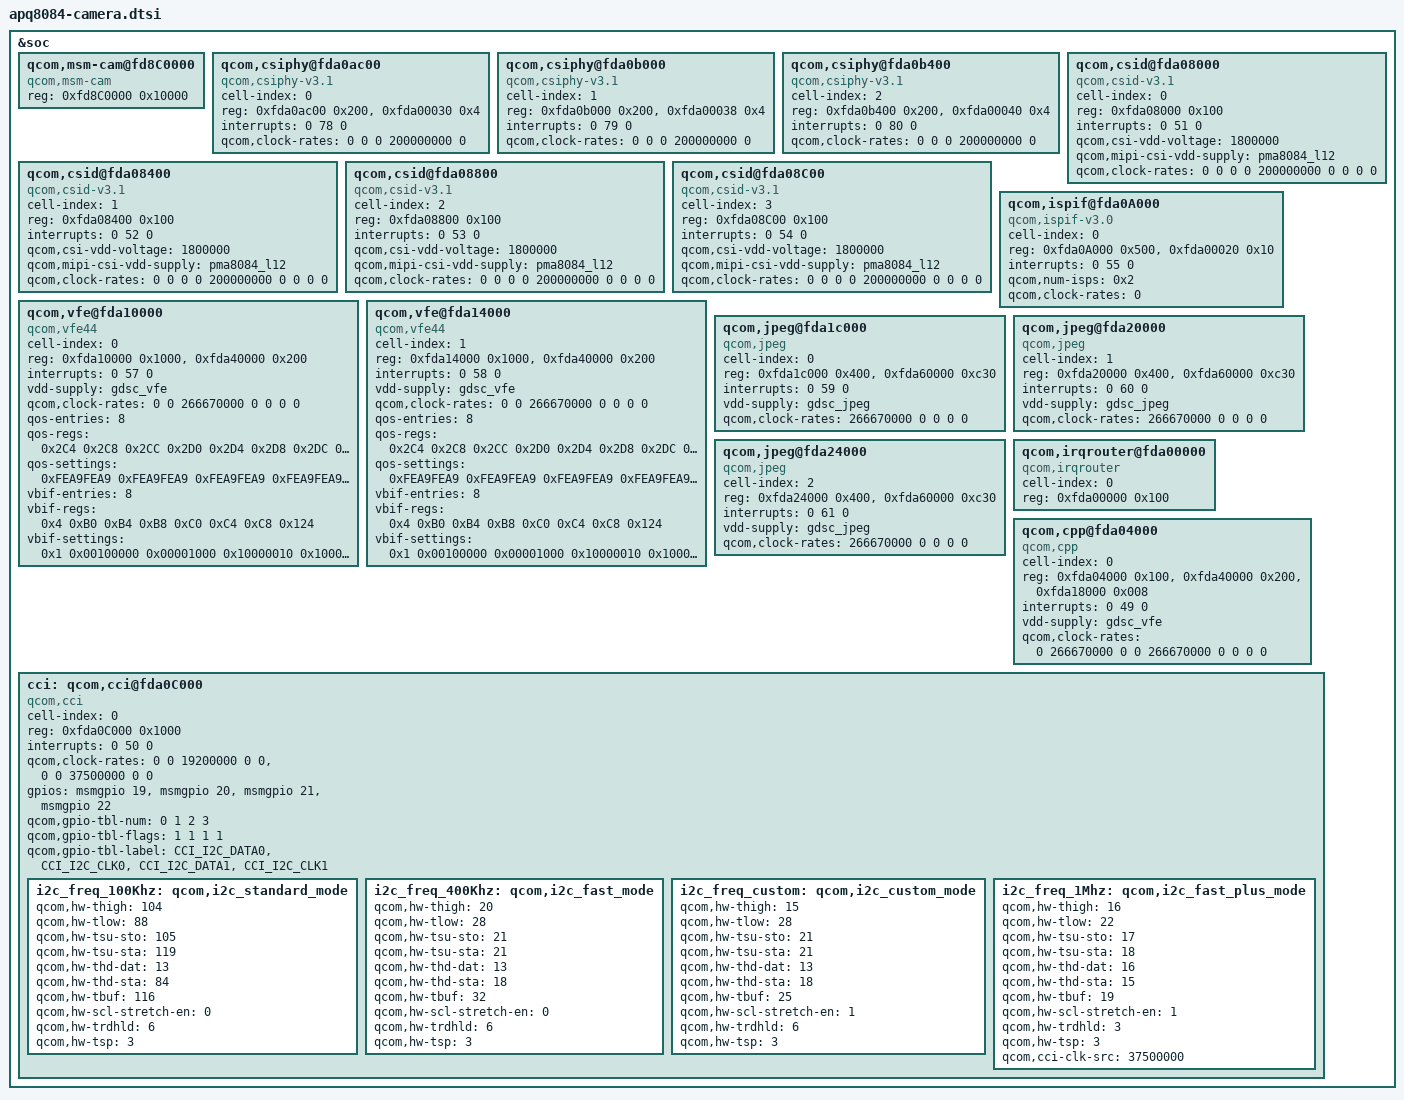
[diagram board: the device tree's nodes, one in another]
/*
 * Copyright (c) 2013-2014, The Linux Foundation. All rights reserved.
 *
 * This program is free software; you can redistribute it and/or modify
 * it under the terms of the GNU General Public License version 2 and
 * only version 2 as published by the Free Software Foundation.
 *
 * This program is distributed in the hope that it will be useful,
 * but WITHOUT ANY WARRANTY; without even the implied warranty of
 * MERCHANTABILITY or FITNESS FOR A PARTICULAR PURPOSE.  See the
 * GNU General Public License for more details.
 */

&soc {
	qcom,msm-cam@fd8C0000 {
		compatible = "qcom,msm-cam";
		reg = <0xfd8C0000 0x10000>;
		reg-names = "msm-cam";
	};

	qcom,csiphy@fda0ac00 {
		cell-index = <0>;
		compatible = "qcom,csiphy-v3.1", "qcom,csiphy";
		reg = <0xfda0ac00 0x200>,
                      <0xfda00030 0x4>;
		reg-names = "csiphy", "csiphy_clk_mux";
		interrupts = <0 78 0>;
		interrupt-names = "csiphy";
		clock-names = "camss_top_ahb_clk",
			"camss_ahb_clk", "ispif_ahb_clk",
			"csiphy_timer_src_clk", "csiphy_timer_clk";
		qcom,clock-rates = <0 0 0 200000000 0>;
	};

	qcom,csiphy@fda0b000 {
		cell-index = <1>;
		compatible = "qcom,csiphy-v3.1", "qcom,csiphy";
		reg = <0xfda0b000 0x200>,
                      <0xfda00038 0x4>;
		reg-names = "csiphy", "csiphy_clk_mux";
		interrupts = <0 79 0>;
		interrupt-names = "csiphy";
		clock-names = "camss_top_ahb_clk",
			"camss_ahb_clk", "ispif_ahb_clk",
			"csiphy_timer_src_clk", "csiphy_timer_clk";
		qcom,clock-rates = <0 0 0 200000000 0>;
	};

	qcom,csiphy@fda0b400 {
		cell-index = <2>;
		compatible = "qcom,csiphy-v3.1", "qcom,csiphy";
		reg = <0xfda0b400 0x200>,
                      <0xfda00040 0x4>;
		reg-names = "csiphy", "csiphy_clk_mux";
		interrupts = <0 80 0>;
		interrupt-names = "csiphy";
		clock-names = "camss_top_ahb_clk",
			"camss_ahb_clk", "ispif_ahb_clk",
			"csiphy_timer_src_clk", "csiphy_timer_clk";
		qcom,clock-rates = <0 0 0 200000000 0>;
	};

	qcom,csid@fda08000  {
		cell-index = <0>;
		compatible = "qcom,csid-v3.1", "qcom,csid";
		reg = <0xfda08000 0x100>;
		reg-names = "csid";
		interrupts = <0 51 0>;
		interrupt-names = "csid";
		qcom,csi-vdd-voltage = <1800000>;
		qcom,mipi-csi-vdd-supply = <&pma8084_l12>;
		clock-names = "camss_top_ahb_clk", "camss_ahb_clk",
			"ispif_ahb_clk", "csi_ahb_clk",
			"csi_src_clk", "csi_clk", "csi_phy_clk",
			"csi_pix_clk", "csi_rdi_clk";
		qcom,clock-rates = <0 0 0 0 200000000 0 0 0 0>;
	};

	qcom,csid@fda08400 {
		cell-index = <1>;
		compatible = "qcom,csid-v3.1", "qcom,csid";
		reg = <0xfda08400 0x100>;
		reg-names = "csid";
		interrupts = <0 52 0>;
		interrupt-names = "csid";
		qcom,csi-vdd-voltage = <1800000>;
		qcom,mipi-csi-vdd-supply = <&pma8084_l12>;
		clock-names = "camss_top_ahb_clk", "camss_ahb_clk",
			"ispif_ahb_clk", "csi_ahb_clk",
			"csi_src_clk", "csi_clk", "csi_phy_clk",
			"csi_pix_clk", "csi_rdi_clk";
		qcom,clock-rates = <0 0 0 0 200000000 0 0 0 0>;
	};

	qcom,csid@fda08800 {
		cell-index = <2>;
		compatible = "qcom,csid-v3.1", "qcom,csid";
		reg = <0xfda08800 0x100>;
		reg-names = "csid";
		interrupts = <0 53 0>;
		interrupt-names = "csid";
		qcom,csi-vdd-voltage = <1800000>;
		qcom,mipi-csi-vdd-supply = <&pma8084_l12>;
		clock-names = "camss_top_ahb_clk", "camss_ahb_clk",
			"ispif_ahb_clk", "csi_ahb_clk",
			"csi_src_clk", "csi_clk", "csi_phy_clk",
			"csi_pix_clk", "csi_rdi_clk";
		qcom,clock-rates = <0 0 0 0 200000000 0 0 0 0>;
	};

	qcom,csid@fda08C00 {
		cell-index = <3>;
		compatible = "qcom,csid-v3.1", "qcom,csid";
		reg = <0xfda08C00 0x100>;
		reg-names = "csid";
		interrupts = <0 54 0>;
		interrupt-names = "csid";
		qcom,csi-vdd-voltage = <1800000>;
		qcom,mipi-csi-vdd-supply = <&pma8084_l12>;
		clock-names = "camss_top_ahb_clk", "camss_ahb_clk",
			"ispif_ahb_clk", "csi_ahb_clk",
			"csi_src_clk", "csi_clk", "csi_phy_clk",
			"csi_pix_clk", "csi_rdi_clk";
		qcom,clock-rates = <0 0 0 0 200000000 0 0 0 0>;
	};

	qcom,ispif@fda0A000 {
		cell-index = <0>;
		compatible = "qcom,ispif-v3.0", "qcom,ispif";
		reg = <0xfda0A000 0x500>,
                      <0xfda00020 0x10>;
		reg-names = "ispif", "csi_clk_mux";
		interrupts = <0 55 0>;
		interrupt-names = "ispif";
		qcom,num-isps = <0x2>;
		clock-names = "ispif_ahb_clk";
		qcom,clock-rates = <0>;
	};

	qcom,vfe@fda10000 {
		cell-index = <0>;
		compatible = "qcom,vfe44";
		reg = <0xfda10000 0x1000>,
			<0xfda40000 0x200>;
		reg-names = "vfe", "vfe_vbif";
		interrupts = <0 57 0>;
		interrupt-names = "vfe";
		vdd-supply = <&gdsc_vfe>;
		clock-names = "camss_top_ahb_clk" , "camss_ahb_clk",
			"vfe_clk_src", "camss_vfe_vfe_clk", "camss_csi_vfe_clk",
			"iface_clk", "bus_clk";
		qcom,clock-rates = <0 0 266670000 0 0 0 0>;
		qos-entries = <8>;
		qos-regs = <0x2C4 0x2C8 0x2CC 0x2D0 0x2D4 0x2D8
				0x2DC 0x2E0>;
		qos-settings = <0xFEA9FEA9 0xFEA9FEA9 0xFEA9FEA9
				0xFEA9FEA9 0xFEA9FEA9 0xFEA9FEA9
				0xFEA9FEA9 0x0001FEA9>;
		vbif-entries = <8>;
		vbif-regs = <0x4 0xB0 0xB4 0xB8 0xC0 0xC4 0xC8 0x124>;
		vbif-settings = <0x1 0x00100000 0x00001000 0x10000010
				0x10000010 0x10100000 0x00101000 0x3>;
	};

	qcom,vfe@fda14000 {
		cell-index = <1>;
		compatible = "qcom,vfe44";
		reg = <0xfda14000 0x1000>,
			<0xfda40000 0x200>;
		reg-names = "vfe", "vfe_vbif";
		interrupts = <0 58 0>;
		interrupt-names = "vfe";
		vdd-supply = <&gdsc_vfe>;
		clock-names = "camss_top_ahb_clk" , "camss_ahb_clk",
			"vfe_clk_src", "camss_vfe_vfe_clk", "camss_csi_vfe_clk",
			"iface_clk", "bus_clk";
		qcom,clock-rates = <0 0 266670000 0 0 0 0>;
		qos-entries = <8>;
		qos-regs = <0x2C4 0x2C8 0x2CC 0x2D0 0x2D4 0x2D8
				0x2DC 0x2E0>;
		qos-settings = <0xFEA9FEA9 0xFEA9FEA9 0xFEA9FEA9
				0xFEA9FEA9 0xFEA9FEA9 0xFEA9FEA9
				0xFEA9FEA9 0x0001FEA9>;
		vbif-entries = <8>;
		vbif-regs = <0x4 0xB0 0xB4 0xB8 0xC0 0xC4 0xC8 0x124>;
		vbif-settings = <0x1 0x00100000 0x00001000 0x10000010
				0x10000010 0x10100000 0x00101000 0x3>;
	};

	qcom,jpeg@fda1c000 {
		cell-index = <0>;
		compatible = "qcom,jpeg";
		reg = <0xfda1c000 0x400>,
			<0xfda60000 0xc30>;
		reg-names = "jpeg";
		interrupts = <0 59 0>;
		interrupt-names = "jpeg";
		vdd-supply = <&gdsc_jpeg>;
		clock-names = "core_clk", "iface_clk", "bus_clk0",
			"camss_ahb_clk", "camss_top_ahb_clk";
		qcom,clock-rates = <266670000 0 0 0 0>;
	};

	qcom,jpeg@fda20000 {
		cell-index = <1>;
		compatible = "qcom,jpeg";
		reg = <0xfda20000 0x400>,
			<0xfda60000 0xc30>;
		reg-names = "jpeg";
		interrupts = <0 60 0>;
		interrupt-names = "jpeg";
		vdd-supply = <&gdsc_jpeg>;
		clock-names = "core_clk", "iface_clk", "bus_clk0",
			"camss_ahb_clk", "camss_top_ahb_clk";
		qcom,clock-rates = <266670000 0 0 0 0>;
	};

	qcom,jpeg@fda24000 {
		cell-index = <2>;
		compatible = "qcom,jpeg";
		reg = <0xfda24000 0x400>,
			<0xfda60000 0xc30>;
		reg-names = "jpeg";
		interrupts = <0 61 0>;
		interrupt-names = "jpeg";
		vdd-supply = <&gdsc_jpeg>;
		clock-names = "core_clk", "iface_clk", "bus_clk0",
			"camss_ahb_clk", "camss_top_ahb_clk";
		qcom,clock-rates = <266670000 0 0 0 0>;
	};

	qcom,irqrouter@fda00000 {
		cell-index = <0>;
		compatible = "qcom,irqrouter";
		reg = <0xfda00000 0x100>;
		reg-names = "irqrouter";
	};

	qcom,cpp@fda04000 {
		cell-index = <0>;
		compatible = "qcom,cpp";
		reg = <0xfda04000 0x100>,
			<0xfda40000 0x200>,
			<0xfda18000 0x008>;
		reg-names = "cpp", "cpp_vbif", "cpp_hw";
		interrupts = <0 49 0>;
		interrupt-names = "cpp";
		vdd-supply = <&gdsc_vfe>;
        clock-names = "camss_top_ahb_clk", "vfe_clk_src",
                           "camss_vfe_vfe_clk", "iface_clk", "cpp_core_clk",
                           "cpp_iface_clk", "cpp_bus_clk", "micro_iface_clk",
                           "camss_ahb_clk";
        qcom,clock-rates = <0 266670000 0 0 266670000 0 0 0 0>;
    };

	cci: qcom,cci@fda0C000 {
		cell-index = <0>;
		compatible = "qcom,cci";
		reg = <0xfda0C000 0x1000>;
		#address-cells = <1>;
		#size-cells = <0>;
		reg-names = "cci";
		interrupts = <0 50 0>;
		interrupt-names = "cci";
        clock-names = "camss_top_ahb_clk", "camss_ahb_clk", "cci_src_clk",
                           "cci_ahb_clk", "cci_clk";
        qcom,clock-rates = <0 0 19200000 0 0>,
			<0 0 37500000 0 0>;
		gpios = <&msmgpio 19 0>,
			<&msmgpio 20 0>,
			<&msmgpio 21 0>,
			<&msmgpio 22 0>;
		qcom,gpio-tbl-num = <0 1 2 3>;
		qcom,gpio-tbl-flags = <1 1 1 1>;
		qcom,gpio-tbl-label = "CCI_I2C_DATA0",
				      "CCI_I2C_CLK0",
				      "CCI_I2C_DATA1",
				      "CCI_I2C_CLK1";
		i2c_freq_100Khz: qcom,i2c_standard_mode {
			status = "disabled";
		};
		i2c_freq_400Khz: qcom,i2c_fast_mode {
			status = "disabled";
		};
		i2c_freq_custom: qcom,i2c_custom_mode {
			status = "disabled";
		};

		i2c_freq_1Mhz: qcom,i2c_fast_plus_mode {
			status = "disabled";
		};

	};
};

&i2c_freq_100Khz {
	qcom,hw-thigh = <104>;
	qcom,hw-tlow = <88>;
	qcom,hw-tsu-sto = <105>;
	qcom,hw-tsu-sta = <119>;
	qcom,hw-thd-dat = <13>;
	qcom,hw-thd-sta = <84>;
	qcom,hw-tbuf = <116>;
	qcom,hw-scl-stretch-en = <0>;
	qcom,hw-trdhld = <6>;
	qcom,hw-tsp = <3>;
	status = "ok";
};

&i2c_freq_400Khz {
	qcom,hw-thigh = <20>;
	qcom,hw-tlow = <28>;
	qcom,hw-tsu-sto = <21>;
	qcom,hw-tsu-sta = <21>;
	qcom,hw-thd-dat = <13>;
	qcom,hw-thd-sta = <18>;
	qcom,hw-tbuf = <32>;
	qcom,hw-scl-stretch-en = <0>;
	qcom,hw-trdhld = <6>;
	qcom,hw-tsp = <3>;
	status = "ok";
};

&i2c_freq_custom {
	qcom,hw-thigh = <15>;
	qcom,hw-tlow = <28>;
	qcom,hw-tsu-sto = <21>;
	qcom,hw-tsu-sta = <21>;
	qcom,hw-thd-dat = <13>;
	qcom,hw-thd-sta = <18>;
	qcom,hw-tbuf = <25>;
	qcom,hw-scl-stretch-en = <1>;
	qcom,hw-trdhld = <6>;
	qcom,hw-tsp = <3>;
	status = "ok";
};

&i2c_freq_1Mhz {
	qcom,hw-thigh = <16>;
	qcom,hw-tlow = <22>;
	qcom,hw-tsu-sto = <17>;
	qcom,hw-tsu-sta = <18>;
	qcom,hw-thd-dat = <16>;
	qcom,hw-thd-sta = <15>;
	qcom,hw-tbuf = <19>;
	qcom,hw-scl-stretch-en = <1>;
	qcom,hw-trdhld = <3>;
	qcom,hw-tsp = <3>;
	qcom,cci-clk-src = <37500000>;
	status = "ok";
};
